# R5SS_CCMR_53210000h register map
Vendor: Texas Instruments
Peripheral module from a debugger description file (folder AM261x).
Registers are 32-bit, read-write, reset 0x0 unless marked. A register's access mark holds for its fields unless they carry their own. Offsets are as the file gives them; lines under a group give offsets from that group; [hi:lo] are bit positions; {n}, {i} and the like mark numbered series; 'fields as' and 'values as' point back to an identical list; <NAME> marks a mode.

## CCMR
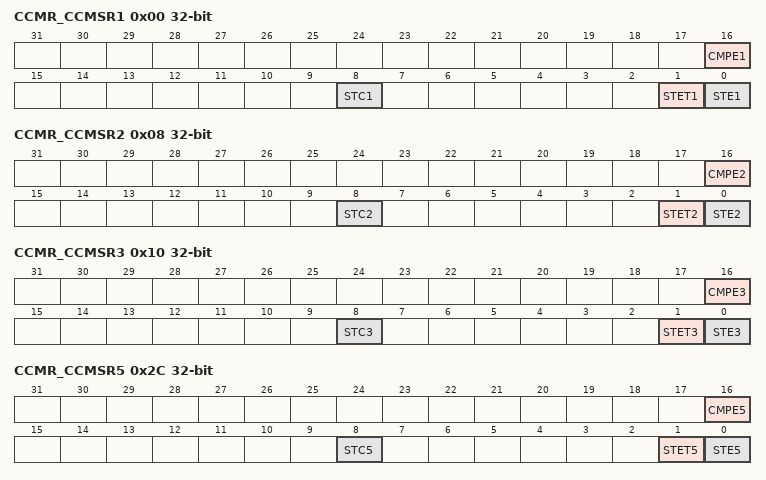
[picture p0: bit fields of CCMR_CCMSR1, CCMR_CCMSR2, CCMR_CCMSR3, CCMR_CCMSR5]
0x00 CCMR_CCMSR1 access per field — CPU Compare Status Register.
  [16] CMPE1 rw — Compare Error0 = CPU signals are identical1= CPU signal compare mismatchWrites '1' to clear this bit
  [8] STC1 rw — Self Test Complete0 = self test on-going if self test mode asserted1 = self test is completeWrites have no effect
  [1] STET1 rw — Self Test Error Type0 = self test failed during Compare Match test1 = self test failed during Compare mismatch testWrites have no effect
  [0] STE1 ro — Self Test Error0 = self test passed1 = self test failedWrites have no effect
0x04 CCMR_CCMKEYR1 — CPU Compare Key Register.
  [3:0] MKEY1 — Mode Key0000= lock step mode0110= self test mode1001= error forcing mode1111= self test error forcing mode
0x08 CCMR_CCMSR2 — VIM Compare Status Register.
  [16] CMPE2 — Compare Error0 = VIM signals are identical1= VIM signal compare mismatchWrites '1' to clear this bit
  [8] STC2 — Self Test Complete0 = self test on-going if self test mode asserted1 = self test is completeWrites have no effect
  [1] STET2 — Self Test Error Type0 = self test failed during Compare Match test1 = self test failed during Compare mismatch testWrites have no effect
  [0] STE2 — Self Test Error0 = self test passed1 = self test failedWrites have no effect
0x0C CCMR_CCMKEYR2 — VIM Compare Key Register.
  [3:0] MKEY2 — Mode Key0000= lock step mode0110= self test mode1001= error forcing mode1111= self test error forcing mode
0x10 CCMR_CCMSR3 access per field — Inactivity Monitor Status Register.
  [16] CMPE3 rw — Compare Error0 = Inactivity monitor signals are identical1= Inactivity monitor signal compare mismatchWrites '1' to clear this bit
  [8] STC3 rw — Self Test Complete0 = self test on-going if self test mode asserted1 = self test is completeWrites have no effect
  [1] STET3 rw — Self Test Error Type0 = self test failed during Compare Match test1 = self test failed during Compare mismatch testWrites have no effect
  [0] STE3 ro — Self Test Error0 = self test passed1 = self test failedWrites have no effect
0x14 CCMR_CCMKEYR3 — Inactivity Monitor Key Register.
  [3:0] MKEY3 — Mode Key0000= lock step mode0110= self test mode1001= error forcing mode1111= self test error forcing mode
0x18 CCMR_CCMPOLCNTRL ro — CPU Compare Polarity Control Register.
  [7:0] POL_INV — This value is used to invert the 8 XOR of the CPU1 to create compare fail in functional active compare mode. User and privilege mode read = Returns current value of the POL INVPrivilege mode write = Update the values of POL INV
0x2C CCMR_CCMSR5 access per field — TMU Compare Status Register.
  [16] CMPE5 rw — Compare Error0 = Inactivity monitor signals are identical1= Inactivity monitor signal compare mismatchWrites '1' to clear this bit
  [8] STC5 rw — Self Test Complete0 = self test on-going if self test mode asserted1 = self test is completeWrites have no effect
  [1] STET5 rw — Self Test Error Type0 = self test failed during Compare Match test1 = self test failed during Compare mismatch testWrites have no effect
  [0] STE5 ro — Self Test Error0 = self test passed1 = self test failedWrites have no effect
0x30 CCMR_CCMKEYR5 — TMU Compare Key Register.
  [3:0] MKEY5 — Mode Key0000= lock step mode0110= self test mode1001= error forcing mode1111= self test error forcing mode
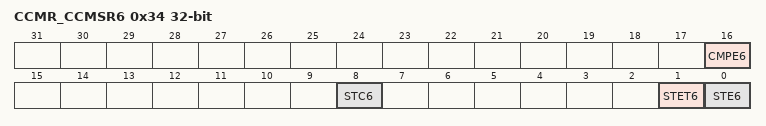
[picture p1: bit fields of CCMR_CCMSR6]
0x34 CCMR_CCMSR6 access per field — RL2 Compare Status Register.
  [16] CMPE6 rw — Compare Error0 = Inactivity monitor signals are identical1= Inactivity monitor signal compare mismatchWrites '1' to clear this bit
  [8] STC6 rw — Self Test Complete0 = self test on-going if self test mode asserted1 = self test is completeWrites have no effect
  [1] STET6 rw — Self Test Error Type0 = self test failed during Compare Match test1 = self test failed during Compare mismatch testWrites have no effect
  [0] STE6 ro — Self Test Error0 = self test passed1 = self test failedWrites have no effect
0x38 CCMR_CCMKEYR6 — RL2 Compare Key Register.
  [3:0] MKEY6 — Mode Key0000= lock step mode0110= self test mode1001= error forcing mode1111= self test error forcing mode
